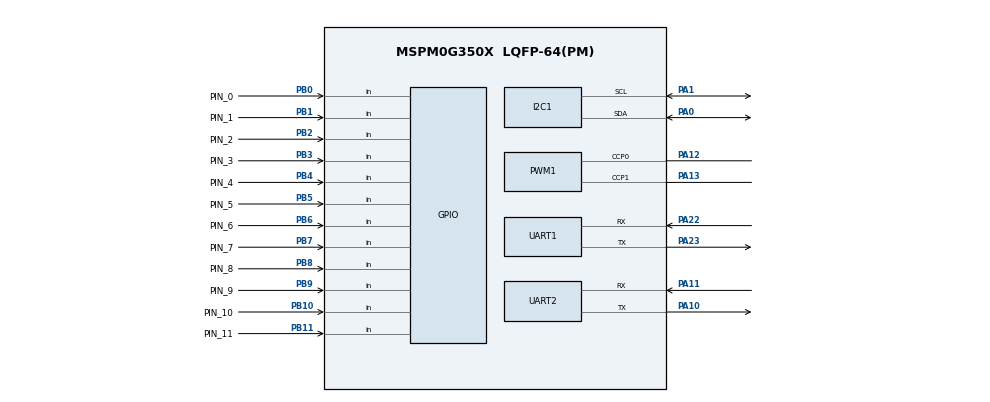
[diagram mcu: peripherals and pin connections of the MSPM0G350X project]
/**
 * @cliArgs --device "MSPM0G350X" --part "Default" --package "LQFP-64(PM)" --product "mspm0_sdk@2.10.00.04"
 * @versions {"tool":"1.26.2+4477"}
 */

/**
 * Import the modules used in this configuration.
 */
const GPIO    = scripting.addModule("/ti/driverlib/GPIO", {}, false);
const GPIO1   = GPIO.addInstance();
const GPIO2   = GPIO.addInstance();
const I2C     = scripting.addModule("/ti/driverlib/I2C", {}, false);
const I2C1    = I2C.addInstance();
const PWM     = scripting.addModule("/ti/driverlib/PWM", {}, false);
const PWM1    = PWM.addInstance();
const SYSCTL  = scripting.addModule("/ti/driverlib/SYSCTL");
const SYSTICK = scripting.addModule("/ti/driverlib/SYSTICK");
const UART    = scripting.addModule("/ti/driverlib/UART", {}, false);
const UART1   = UART.addInstance();
const UART2   = UART.addInstance();

/**
 * Write custom configuration values to the imported modules.
 */
GPIO1.$name                         = "LED";
GPIO1.port                          = "PORTB";
GPIO1.associatedPins[0].$name       = "PIN_22";
GPIO1.associatedPins[0].assignedPin = "22";

const Board = scripting.addModule("/ti/driverlib/Board", {}, false);

GPIO2.$name                          = "Grays";
GPIO2.port                           = "PORTB";
GPIO2.associatedPins.create(12);
GPIO2.associatedPins[0].$name        = "PIN_0";
GPIO2.associatedPins[0].direction    = "INPUT";
GPIO2.associatedPins[0].pin.$assign  = "PB0";
GPIO2.associatedPins[1].$name        = "PIN_1";
GPIO2.associatedPins[1].direction    = "INPUT";
GPIO2.associatedPins[1].pin.$assign  = "PB1";
GPIO2.associatedPins[2].$name        = "PIN_2";
GPIO2.associatedPins[2].direction    = "INPUT";
GPIO2.associatedPins[2].pin.$assign  = "PB2";
GPIO2.associatedPins[3].$name        = "PIN_3";
GPIO2.associatedPins[3].direction    = "INPUT";
GPIO2.associatedPins[3].pin.$assign  = "PB3";
GPIO2.associatedPins[4].$name        = "PIN_4";
GPIO2.associatedPins[4].direction    = "INPUT";
GPIO2.associatedPins[4].pin.$assign  = "PB4";
GPIO2.associatedPins[5].$name        = "PIN_5";
GPIO2.associatedPins[5].direction    = "INPUT";
GPIO2.associatedPins[5].pin.$assign  = "PB5";
GPIO2.associatedPins[6].$name        = "PIN_6";
GPIO2.associatedPins[6].direction    = "INPUT";
GPIO2.associatedPins[6].pin.$assign  = "PB6";
GPIO2.associatedPins[7].$name        = "PIN_7";
GPIO2.associatedPins[7].direction    = "INPUT";
GPIO2.associatedPins[7].pin.$assign  = "PB7";
GPIO2.associatedPins[8].$name        = "PIN_8";
GPIO2.associatedPins[8].direction    = "INPUT";
GPIO2.associatedPins[8].pin.$assign  = "PB8";
GPIO2.associatedPins[9].$name        = "PIN_9";
GPIO2.associatedPins[9].direction    = "INPUT";
GPIO2.associatedPins[9].pin.$assign  = "PB9";
GPIO2.associatedPins[10].$name       = "PIN_10";
GPIO2.associatedPins[10].direction   = "INPUT";
GPIO2.associatedPins[10].pin.$assign = "PB10";
GPIO2.associatedPins[11].$name       = "PIN_11";
GPIO2.associatedPins[11].direction   = "INPUT";
GPIO2.associatedPins[11].pin.$assign = "PB11";

I2C1.$name                             = "OLED";
I2C1.basicEnableController             = true;
I2C1.peripheral.$assign                = "I2C0";
I2C1.peripheral.sdaPin.$assign         = "PA0";
I2C1.peripheral.sclPin.$assign         = "PA1";
I2C1.sdaPinConfig.hideOutputInversion  = scripting.forceWrite(false);
I2C1.sdaPinConfig.onlyInternalResistor = scripting.forceWrite(false);
I2C1.sdaPinConfig.passedPeripheralType = scripting.forceWrite("Digital");
I2C1.sdaPinConfig.$name                = "ti_driverlib_gpio_GPIOPinGeneric4";
I2C1.sclPinConfig.hideOutputInversion  = scripting.forceWrite(false);
I2C1.sclPinConfig.onlyInternalResistor = scripting.forceWrite(false);
I2C1.sclPinConfig.passedPeripheralType = scripting.forceWrite("Digital");
I2C1.sclPinConfig.$name                = "ti_driverlib_gpio_GPIOPinGeneric5";

PWM1.$name                      = "PWM_0";
PWM1.clockPrescale              = 25;
PWM1.timerCount                 = 128;
PWM1.peripheral.ccp0Pin.$assign = "PA12";
PWM1.peripheral.ccp1Pin.$assign = "PA13";
PWM1.PWM_CHANNEL_0.$name        = "ti_driverlib_pwm_PWMTimerCC0";
PWM1.PWM_CHANNEL_0.dutyCycle    = 100;
PWM1.PWM_CHANNEL_1.$name        = "ti_driverlib_pwm_PWMTimerCC1";
PWM1.PWM_CHANNEL_1.dutyCycle    = 100;
PWM1.ccp0PinConfig.$name        = "ti_driverlib_gpio_GPIOPinGeneric6";
PWM1.ccp1PinConfig.$name        = "ti_driverlib_gpio_GPIOPinGeneric7";

SYSCTL.forceDefaultClkConfig = true;

SYSTICK.periodEnable  = true;
SYSTICK.period        = 32;
SYSTICK.systickEnable = true;

UART1.targetBaudRate                   = 115200;
UART1.$name                            = "UART_2";
UART1.peripheral.$assign               = "UART2";
UART1.peripheral.rxPin.$assign         = "PA22";
UART1.peripheral.txPin.$assign         = "PA23";
UART1.txPinConfig.direction            = scripting.forceWrite("OUTPUT");
UART1.txPinConfig.hideOutputInversion  = scripting.forceWrite(false);
UART1.txPinConfig.onlyInternalResistor = scripting.forceWrite(false);
UART1.txPinConfig.passedPeripheralType = scripting.forceWrite("Digital");
UART1.txPinConfig.$name                = "ti_driverlib_gpio_GPIOPinGeneric0";
UART1.rxPinConfig.hideOutputInversion  = scripting.forceWrite(false);
UART1.rxPinConfig.onlyInternalResistor = scripting.forceWrite(false);
UART1.rxPinConfig.passedPeripheralType = scripting.forceWrite("Digital");
UART1.rxPinConfig.$name                = "ti_driverlib_gpio_GPIOPinGeneric1";

UART2.$name                            = "UART_0";
UART2.targetBaudRate                   = 115200;
UART2.peripheral.rxPin.$assign         = "PA11";
UART2.peripheral.txPin.$assign         = "PA10";
UART2.txPinConfig.direction            = scripting.forceWrite("OUTPUT");
UART2.txPinConfig.hideOutputInversion  = scripting.forceWrite(false);
UART2.txPinConfig.onlyInternalResistor = scripting.forceWrite(false);
UART2.txPinConfig.passedPeripheralType = scripting.forceWrite("Digital");
UART2.txPinConfig.$name                = "ti_driverlib_gpio_GPIOPinGeneric2";
UART2.rxPinConfig.hideOutputInversion  = scripting.forceWrite(false);
UART2.rxPinConfig.onlyInternalResistor = scripting.forceWrite(false);
UART2.rxPinConfig.passedPeripheralType = scripting.forceWrite("Digital");
UART2.rxPinConfig.$name                = "ti_driverlib_gpio_GPIOPinGeneric3";

/**
 * Pinmux solution for unlocked pins/peripherals. This ensures that minor changes to the automatic solver in a future
 * version of the tool will not impact the pinmux you originally saw.  These lines can be completely deleted in order to
 * re-solve from scratch.
 */
GPIO1.associatedPins[0].pin.$suggestSolution = "PB22";
Board.peripheral.$suggestSolution            = "DEBUGSS";
Board.peripheral.swclkPin.$suggestSolution   = "PA20";
Board.peripheral.swdioPin.$suggestSolution   = "PA19";
PWM1.peripheral.$suggestSolution             = "TIMG0";
SYSCTL.peripheral.$suggestSolution           = "SYSCTL";
UART2.peripheral.$suggestSolution            = "UART0";
